# TC37X register map
File version: 1.0.0
CPU: CM4 r0p1, little endian, MPU, FPU, VTOR, 3 interrupt priority bits
Registers are 16-bit, read-write, reset 0x0 unless marked. A register's access mark holds for its fields unless they carry their own. Offsets are from the block's base; [hi:lo] are bit positions; {n}, {i} and the like mark numbered series.

## GPT120 — ce_gptonetwo
Base 0xF0001800
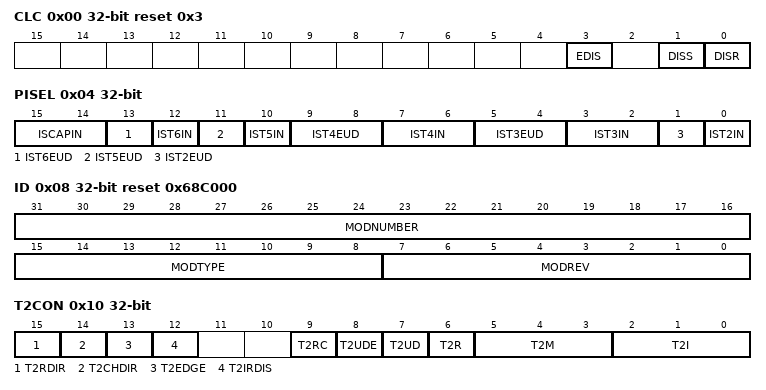
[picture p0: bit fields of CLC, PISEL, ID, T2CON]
0x00 CLC 32-bit reset 0x3 — Clock Control Register
  [3] EDIS — Sleep Mode Enable Control - EDIS
  [1] DISS ro — Module Disable Status Bit - DISS
  [0] DISR — Module Disable Request Bit - DISR
0x04 PISEL 32-bit — Port Input Select Register
  [15:14] ISCAPIN — Input Select for CAPIN - ISCAPIN
  [13] IST6EUD — Input Select for T6EUD - IST6EUD
  [12] IST6IN — Input Select for T6IN - IST6IN
  [11] IST5EUD — Input Select for T5EUD - IST5EUD
  [10] IST5IN — Input Select for T5IN - IST5IN
  [9:8] IST4EUD — Input Select for T4EUD - IST4EUD
  [7:6] IST4IN — Input Select for T4IN - IST4IN
  [5:4] IST3EUD — Input Select for T3EUD - IST3EUD
  [3:2] IST3IN — Input Select for T3IN - IST3IN
  [1] IST2EUD — Input Select for T2EUD - IST2EUD
  [0] IST2IN — Input Select for T2IN - IST2IN
0x08 ID 32-bit ro reset 0x68C000 (reset mask 0xFFFFFF00) — Identification Register
  [31:16] MODNUMBER — Module Number - MODNUMBER
  [15:8] MODTYPE — Module Type - MODTYPE
  [7:0] MODREV — Module Revision Number - MODREV
0x10 T2CON 32-bit — Timer T2 Control Register
  [15] T2RDIR ro — Timer T2 Rotation Direction - T2RDIR
  [14] T2CHDIR — Timer T2 Count Direction Change - T2CHDIR
  [13] T2EDGE — Timer T2 Edge Detection - T2EDGE
  [12] T2IRDIS — Timer T2 Interrupt Disable - T2IRDIS
  [9] T2RC — Timer T2 Remote Control - T2RC
  [8] T2UDE — Timer T2 External Up/Down Enable - T2UDE
  [7] T2UD — Timer T2 Up/Down Control - T2UD
  [6] T2R — Timer T2 Run Bit - T2R
  [5:3] T2M — Timer T2 Mode Control (Basic Operating Mode) - T2M
  [2:0] T2I — Timer T2 Input Parameter Selection - T2I
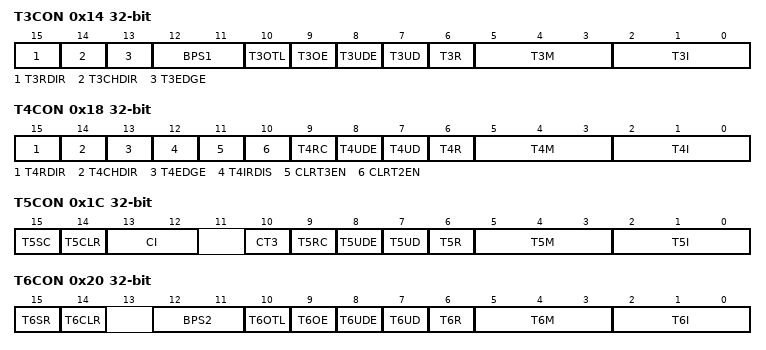
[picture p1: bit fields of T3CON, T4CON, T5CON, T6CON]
0x14 T3CON 32-bit — Timer T3 Control Register
  [15] T3RDIR ro — Timer T3 Rotation Direction Flag - T3RDIR
  [14] T3CHDIR — Timer T3 Count Direction Change Flag - T3CHDIR
  [13] T3EDGE — Timer T3 Edge Detection Flag - T3EDGE
  [12:11] BPS1 — GPT1 Block Prescaler Control - BPS1
  [10] T3OTL — Timer T3 Overflow Toggle Latch - T3OTL
  [9] T3OE — Overflow/Underflow Output Enable - T3OE
  [8] T3UDE — Timer T3 External Up/Down Enable - T3UDE
  [7] T3UD — Timer T3 Up/Down Control - T3UD
  [6] T3R — Timer T3 Run Bit - T3R
  [5:3] T3M — Timer T3 Mode Control - T3M
  [2:0] T3I — Timer T3 Input Parameter Selection - T3I
0x18 T4CON 32-bit — Timer T4 Control Register
  [15] T4RDIR ro — Timer T4 Rotation Direction - T4RDIR
  [14] T4CHDIR — Timer T4 Count Direction Change - T4CHDIR
  [13] T4EDGE — Timer T4 Edge Detection - T4EDGE
  [12] T4IRDIS — Timer T4 Interrupt Disable - T4IRDIS
  [11] CLRT3EN — Clear Timer T3 Enable - CLRT3EN
  [10] CLRT2EN — Clear Timer T2 Enable - CLRT2EN
  [9] T4RC — Timer T4 Remote Control - T4RC
  [8] T4UDE — Timer T4 External Up/Down Enable - T4UDE
  [7] T4UD — Timer T4 Up/Down Control - T4UD
  [6] T4R — Timer T4 Run Bit - T4R
  [5:3] T4M — Timer T4 Mode Control (Basic Operating Mode) - T4M
  [2:0] T4I — Timer T4 Input Parameter Selection - T4I
0x1C T5CON 32-bit — Timer T5 Control Register
  [15] T5SC — Timer T5 Capture Mode Enable - T5SC
  [14] T5CLR — Timer T5 Clear Enable Bit - T5CLR
  [13:12] CI — Register CAPREL Capture Trigger Selection - CI
  [10] CT3 — Timer T3 Capture Trigger Enable - CT3
  [9] T5RC — Timer T5 Remote Control - T5RC
  [8] T5UDE — Timer T5 External Up/Down Enable - T5UDE
  [7] T5UD — Timer T5 Up/Down Control - T5UD
  [6] T5R — Timer T5 Run Bit - T5R
  [5:3] T5M — Timer T5 Mode Control (Basic Operating Mode) - T5M
  [2:0] T5I — Timer T5 Input Parameter Selection - T5I
0x20 T6CON 32-bit — Timer T6 Control Register
  [15] T6SR — Timer T6 Reload Mode Enable - T6SR
  [14] T6CLR — Timer T6 Clear Enable Bit - T6CLR
  [12:11] BPS2 — GPT2 Block Prescaler Control - BPS2
  [10] T6OTL — Timer T6 Overflow Toggle Latch - T6OTL
  [9] T6OE — Overflow/Underflow Output Enable - T6OE
  [8] T6UDE — Timer T6 External Up/Down Enable - T6UDE
  [7] T6UD — Timer T6 Up/Down Control - T6UD
  [6] T6R — Timer T6 Run Bit - T6R
  [5:3] T6M — Timer T6 Mode Control (Basic Operating Mode) - T6M
  [2:0] T6I — Timer T6 Input Parameter Selection - T6I
0x30 CAPREL 32-bit — Capture and Reload Register
  [15:0] CAPREL — Current reload value or Captured value - CAPREL
{0x2C+4i} T{i} 32-bit (i=2..6) — Timer T{i} Register
  [15:0] T{i} — Timer T{i} - T{i}
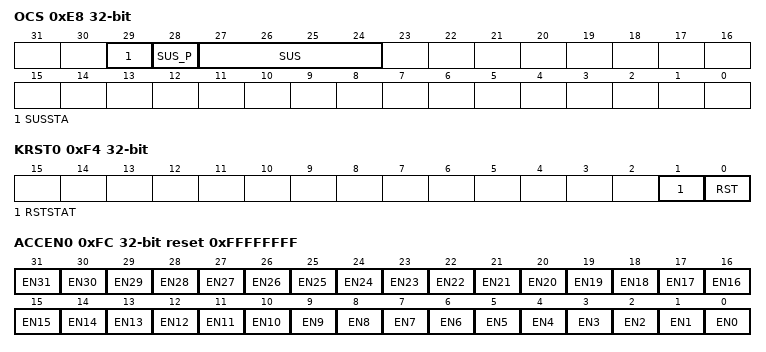
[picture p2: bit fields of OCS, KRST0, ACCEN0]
0xE8 OCS 32-bit — OCDS Control and Status Register
  [29] SUSSTA ro — Suspend State - SUSSTA
  [28] SUS_P wo — SUS Write Protection - SUS_P
  [27:24] SUS — OCDS Suspend Control - SUS
0xEC KRSTCLR 32-bit wo — Kernel Reset Status Clear Register
  [0] CLR — Kernel Reset Status Clear - CLR
0xF0 KRST1 32-bit — Kernel Reset Register 1
  [0] RST — Kernel Reset - RST
0xF4 KRST0 32-bit — Kernel Reset Register 0
  [1] RSTSTAT ro — Kernel Reset Status - RSTSTAT
  [0] RST — Kernel Reset - RST
0xFC ACCEN0 32-bit reset 0xFFFFFFFF — Access Enable Register 0
  [n] EN{n} (n=0..31) — Access Enable for Master TAG ID {n} - EN{n}
